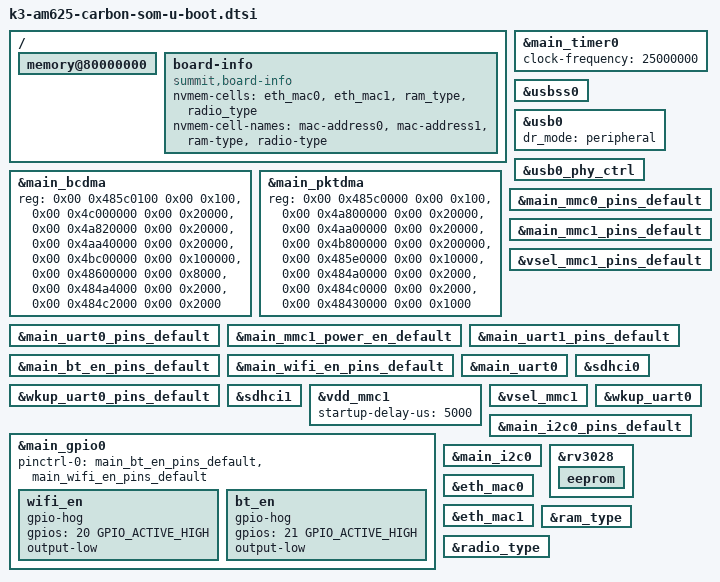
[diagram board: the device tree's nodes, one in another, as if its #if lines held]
// SPDX-License-Identifier: GPL-2.0
/*
 * Common AM625 Carbon dts file for SPLs
 * Copyright (C) 2024 Ezurio LLC
 */

#include "k3-am625-carbon-som-binman.dtsi"

/ {
	memory@80000000 {
		bootph-pre-ram;
	};

	board-info {
		compatible = "summit,board-info";
		bootph-all;

		nvmem-cells = <&eth_mac0>, <&eth_mac1>, <&ram_type>,
			<&radio_type>;
		nvmem-cell-names = "mac-address0", "mac-address1", "ram-type",
			"radio-type";
	};
};

&main_timer0 {
	clock-frequency = <25000000>;
};

&main_bcdma {
	reg = <0x00 0x485c0100 0x00 0x100>,
	      <0x00 0x4c000000 0x00 0x20000>,
	      <0x00 0x4a820000 0x00 0x20000>,
	      <0x00 0x4aa40000 0x00 0x20000>,
	      <0x00 0x4bc00000 0x00 0x100000>,
	      <0x00 0x48600000 0x00 0x8000>,
	      <0x00 0x484a4000 0x00 0x2000>,
	      <0x00 0x484c2000 0x00 0x2000>;
	reg-names = "gcfg", "bchanrt", "rchanrt", "tchanrt",
		    "ringrt" , "cfg", "tchan", "rchan";
};

&main_pktdma {
	reg = <0x00 0x485c0000 0x00 0x100>,
	      <0x00 0x4a800000 0x00 0x20000>,
	      <0x00 0x4aa00000 0x00 0x20000>,
	      <0x00 0x4b800000 0x00 0x200000>,
	      <0x00 0x485e0000 0x00 0x10000>,
	      <0x00 0x484a0000 0x00 0x2000>,
	      <0x00 0x484c0000 0x00 0x2000>,
	      <0x00 0x48430000 0x00 0x1000>;
	reg-names = "gcfg", "rchanrt", "tchanrt", "ringrt",
		    "cfg", "tchan", "rchan", "rflow";
	bootph-all;
};

#ifdef CONFIG_SPL_DFU
/* Required for USB DFU Boot */
&usbss0 {
	bootph-all;
};

&usb0 {
	dr_mode = "peripheral";
	bootph-all;
};

&usb0_phy_ctrl {
	bootph-all;
};
#endif

&main_mmc0_pins_default {
	bootph-all;
};

&main_mmc1_pins_default {
	bootph-all;
};

&main_uart0_pins_default {
	bootph-all;
};

&main_mmc1_power_en_default {
	bootph-all;
};

&vsel_mmc1_pins_default {
	bootph-all;
};

&main_uart1_pins_default {
	bootph-pre-ram;
};

&main_bt_en_pins_default {
	bootph-all;
};

&main_wifi_en_pins_default {
	bootph-all;
};

&main_uart0 {
	bootph-all;
};

&wkup_uart0_pins_default {
	bootph-pre-ram;
};

&sdhci0 {
	bootph-all;
};

&sdhci1 {
	bootph-all;
};

&vdd_mmc1 {
	bootph-all;
	startup-delay-us = <5000>;
};

&vsel_mmc1 {
	bootph-all;
};

&wkup_uart0 {
	bootph-pre-ram;
};

&main_gpio0 {
	bootph-all;
	pinctrl-names = "default";
	pinctrl-0 = <&main_bt_en_pins_default>, <&main_wifi_en_pins_default>;

	wifi_en {
		bootph-pre-ram;
		gpio-hog;
		gpios = <20 GPIO_ACTIVE_HIGH>;
		output-low;
	};

	bt_en {
		bootph-pre-ram;
		gpio-hog;
		gpios = <21 GPIO_ACTIVE_HIGH>;
		output-low;
	};
};

&main_i2c0_pins_default {
	bootph-all;
};

&main_i2c0 {
	bootph-all;
};

&rv3028 {
	bootph-all;

	eeprom {
		bootph-all;
	};
};

&eth_mac0 {
	bootph-all;
};

&eth_mac1 {
	bootph-all;
};

&ram_type {
	bootph-all;
};

&radio_type {
	bootph-all;
};
